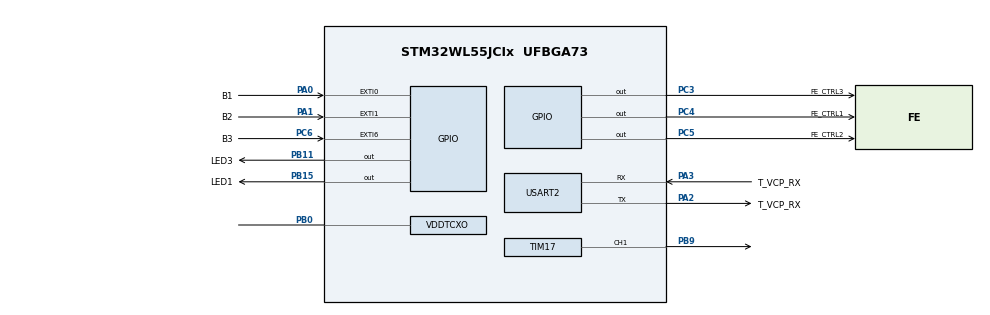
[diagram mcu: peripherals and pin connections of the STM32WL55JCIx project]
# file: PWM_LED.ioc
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Mcu.Family=STM32WL
Mcu.Name=STM32WL55JCIx
Mcu.Package=UFBGA73
NVIC.PriorityGroup=NVIC_PRIORITYGROUP_4
NVIC.TIM17_IRQn=true\:0\:0\:false\:false\:true\:true\:true\:true
OSC_IN.Mode=HSE-TCXO
OSC_IN.Signal=RCC_OSC_IN
PA0.GPIO_Label=B1
PA0.GPIO_ModeDefaultEXTI=GPIO_MODE_IT_FALLING
PA0.GPIO_PuPd=GPIO_PULLUP
PA0.Signal=GPXTI0
PA1.GPIO_Label=B2
PA1.GPIO_ModeDefaultEXTI=GPIO_MODE_IT_FALLING
PA1.GPIO_PuPd=GPIO_PULLUP
PA1.Signal=GPXTI1
PA13.Mode=Serial_Wire
PA13.Signal=DEBUG_JTMS-SWDIO
PA14.Mode=Serial_Wire
PA14.Signal=DEBUG_JTCK-SWCLK
PA2.GPIO_Label=T_VCP_RX
PA2.Mode=Asynchronous
PA2.Signal=USART2_TX
PA3.GPIO_Label=T_VCP_RX
PA3.Mode=Asynchronous
PA3.Signal=USART2_RX
PB0-VDD_TCXO.Mode=HSE-TCXO
PB0-VDD_TCXO.Signal=VDDTCXO
PB11.GPIO_Label=LED3
PB11.GPIO_Speed=GPIO_SPEED_FREQ_HIGH
PB11.Signal=GPIO_Output
PB15.GPIO_Label=LED1
PB15.GPIO_Speed=GPIO_SPEED_FREQ_HIGH
PB15.Signal=GPIO_Output
PB9.GPIO_Speed=GPIO_SPEED_FREQ_HIGH
PB9.Signal=S_TIM17_CH1
PC14-OSC32_IN.Mode=LSE-External-Oscillator
PC14-OSC32_IN.Signal=RCC_OSC32_IN
PC15-OSC32_OUT.Mode=LSE-External-Oscillator
PC15-OSC32_OUT.Signal=RCC_OSC32_OUT
PC3.GPIO_Label=FE_CTRL3
PC3.GPIO_Speed=GPIO_SPEED_FREQ_VERY_HIGH
PC3.Signal=GPIO_Output
PC4.GPIO_Label=FE_CTRL1
PC4.GPIO_Speed=GPIO_SPEED_FREQ_VERY_HIGH
PC4.Signal=GPIO_Output
PC5.GPIO_Label=FE_CTRL2
PC5.GPIO_Speed=GPIO_SPEED_FREQ_VERY_HIGH
PC5.Signal=GPIO_Output
PC6.GPIO_Label=B3
PC6.GPIO_ModeDefaultEXTI=GPIO_MODE_IT_FALLING
PC6.GPIO_PuPd=GPIO_PULLUP
PC6.Signal=GPXTI6
ProjectManager.HeapSize=0x200
ProjectManager.StackSize=0x400
ProjectManager.TargetToolchain=STM32CubeIDE
RCC.HSE_VALUE=32000000
RCC.HSI_VALUE=16000000
RCC.LSE_VALUE=32768
RCC.VCOOutputFreq_Value=32000000
SH.S_TIM17_CH1.0=TIM17_CH1,PWM Generation1 CH1
TIM17.Channel=TIM_CHANNEL_1
USART2.VirtualMode-Asynchronous=VM_ASYNC
VP_TIM17_VS_ClockSourceINT.Mode=Enable_Timer
board=NUCLEO-WL55JC1

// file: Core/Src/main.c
/* USER CODE BEGIN Header */
/**
  ******************************************************************************
  * @file           : main.c
  * @brief          : Main program body
  ******************************************************************************
  * @attention
  *
  * Copyright (c) 2023 STMicroelectronics.
  * All rights reserved.
  *
  * This software is licensed under terms that can be found in the LICENSE file
  * in the root directory of this software component.
  * If no LICENSE file comes with this software, it is provided AS-IS.
  *
  ******************************************************************************
  */
/* USER CODE END Header */
#include "main.h"
#include "tim.h"
#include "usart.h"
#include "gpio.h"

void SystemClock_Config(void);

int main(void)
{

  /* MCU Configuration--------------------------------------------------------*/

  /* Reset of all peripherals, Initializes the Flash interface and the Systick. */
  HAL_Init();

  /* Configure the system clock */
  SystemClock_Config();

  /* Initialize all configured peripherals */
  MX_GPIO_Init();
  MX_USART2_UART_Init();
  MX_TIM17_Init();
  /* USER CODE BEGIN 2 */
  HAL_TIM_PWM_Start(&htim17, TIM_CHANNEL_1);
  /* USER CODE END 2 */

  /* Infinite loop */
  /* USER CODE BEGIN WHILE */
  while (1)
  {
	for (uint16_t i = 0; i < UINT16_MAX; i++)
	{
	  __HAL_TIM_SET_COMPARE(&htim17, TIM_CHANNEL_1, i < UINT16_MAX / 2 ? i : UINT16_MAX - i);

	  for (uint16_t delay = 0; delay < 10; delay++);
	}
    /* USER CODE END WHILE */

  }
}

void SystemClock_Config(void)
{
  RCC_OscInitTypeDef RCC_OscInitStruct = {0};
  RCC_ClkInitTypeDef RCC_ClkInitStruct = {0};

  /** Configure LSE Drive Capability
  */
  HAL_PWR_EnableBkUpAccess();
  __HAL_RCC_LSEDRIVE_CONFIG(RCC_LSEDRIVE_LOW);

  /** Configure the main internal regulator output voltage
  */
  __HAL_PWR_VOLTAGESCALING_CONFIG(PWR_REGULATOR_VOLTAGE_SCALE2);

  /** Initializes the CPU, AHB and APB buses clocks
  */
  RCC_OscInitStruct.OscillatorType = RCC_OSCILLATORTYPE_LSE|RCC_OSCILLATORTYPE_MSI;
  RCC_OscInitStruct.LSEState = RCC_LSE_ON;
  RCC_OscInitStruct.MSIState = RCC_MSI_ON;
  RCC_OscInitStruct.MSICalibrationValue = RCC_MSICALIBRATION_DEFAULT;
  RCC_OscInitStruct.MSIClockRange = RCC_MSIRANGE_6;
  RCC_OscInitStruct.PLL.PLLState = RCC_PLL_NONE;
  if (HAL_RCC_OscConfig(&RCC_OscInitStruct) != HAL_OK)
  {
    Error_Handler();
  }

  /** Configure the SYSCLKSource, HCLK, PCLK1 and PCLK2 clocks dividers
  */
  RCC_ClkInitStruct.ClockType = RCC_CLOCKTYPE_HCLK3|RCC_CLOCKTYPE_HCLK
                              |RCC_CLOCKTYPE_SYSCLK|RCC_CLOCKTYPE_PCLK1
                              |RCC_CLOCKTYPE_PCLK2;
  RCC_ClkInitStruct.SYSCLKSource = RCC_SYSCLKSOURCE_MSI;
  RCC_ClkInitStruct.AHBCLKDivider = RCC_SYSCLK_DIV1;
  RCC_ClkInitStruct.APB1CLKDivider = RCC_HCLK_DIV1;
  RCC_ClkInitStruct.APB2CLKDivider = RCC_HCLK_DIV1;
  RCC_ClkInitStruct.AHBCLK3Divider = RCC_SYSCLK_DIV1;

  if (HAL_RCC_ClockConfig(&RCC_ClkInitStruct, FLASH_LATENCY_0) != HAL_OK)
  {
    Error_Handler();
  }
}

void Error_Handler(void)
{
  __disable_irq();
  while (1)
  {
  }
}
